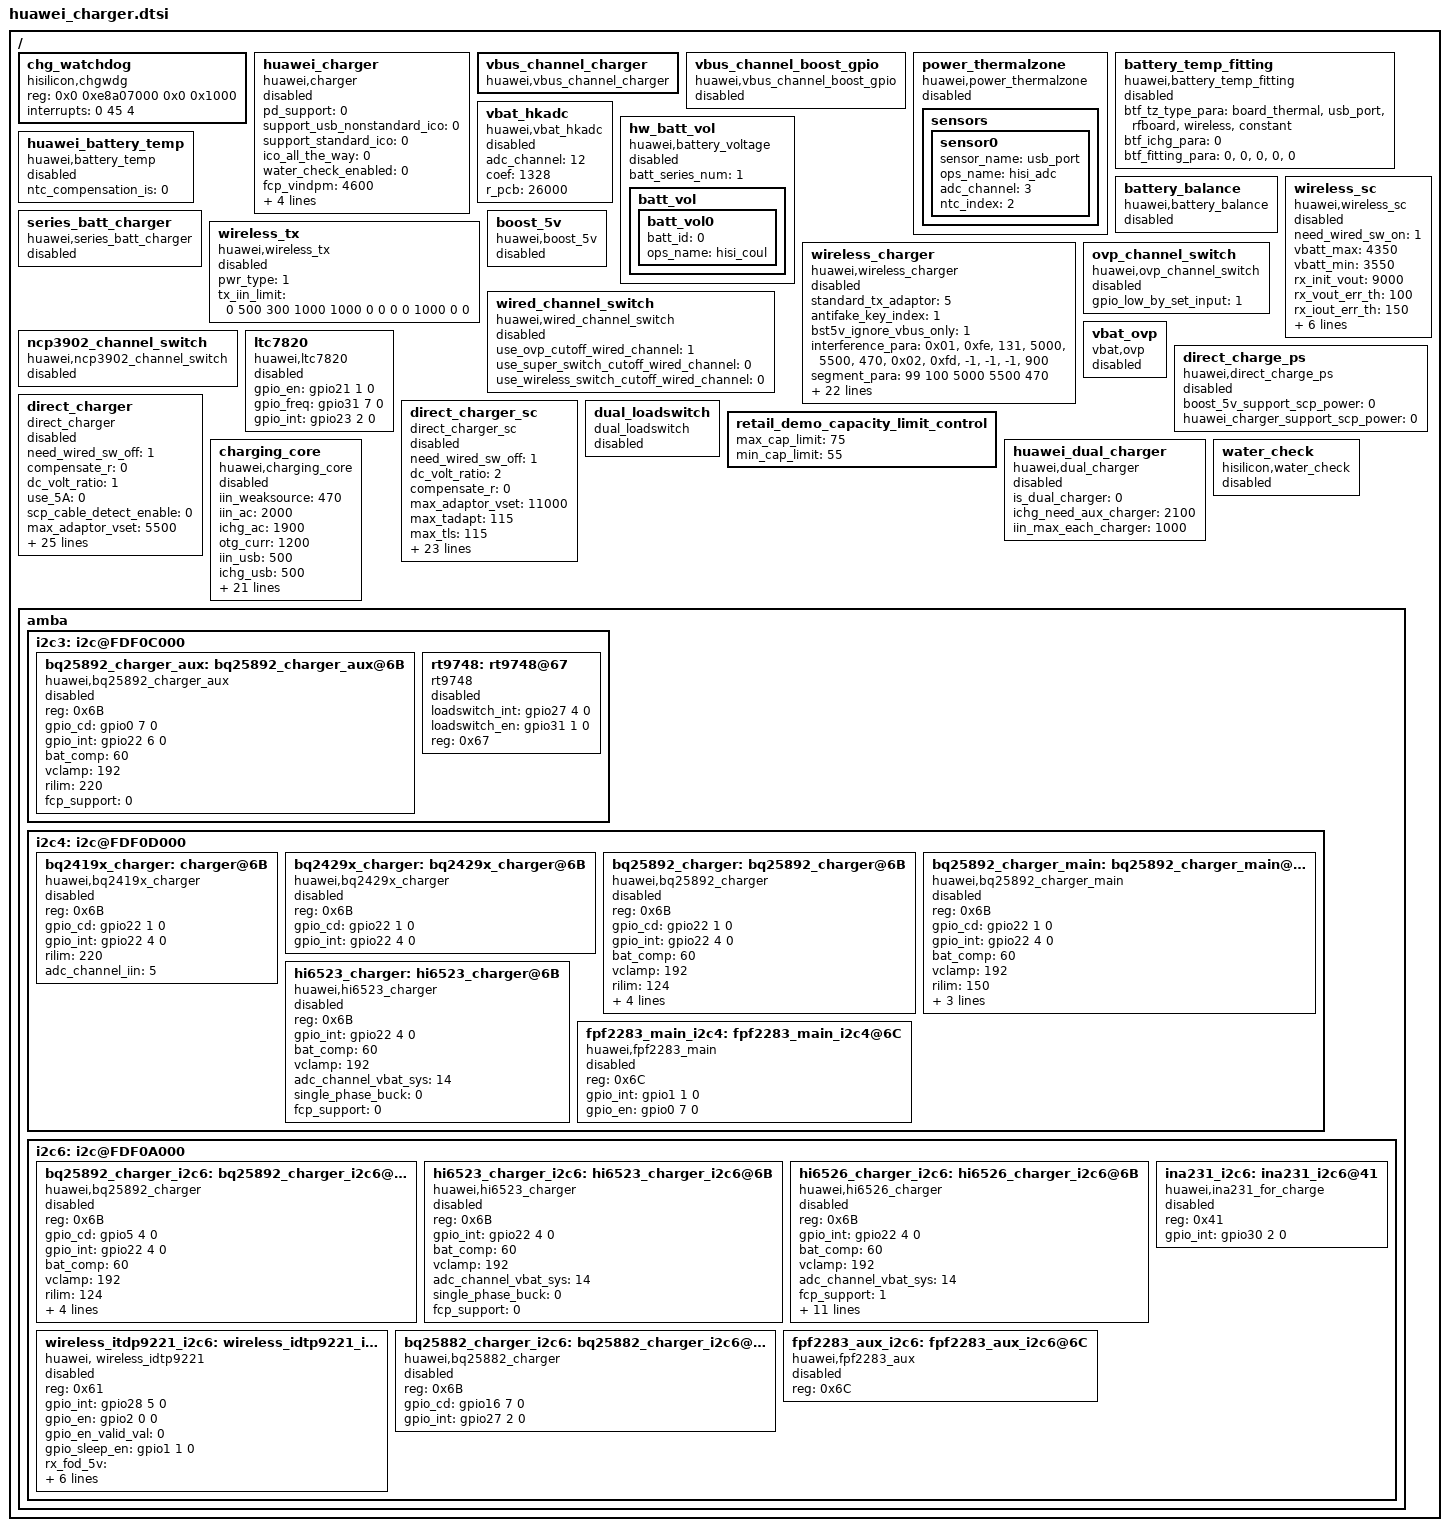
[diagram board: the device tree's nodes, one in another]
/ {
	chg_watchdog {
		compatible = "hisilicon,chgwdg";
		reg = <0x0 0xe8a07000 0x0 0x1000>;
		interrupts = <0 45 4>;
		status = "ok";
	};
	huawei_charger: huawei_charger{
		compatible = "huawei,charger";
		pd_support = <0>;
		support_usb_nonstandard_ico = <0>;
		support_standard_ico = <0>;
		ico_all_the_way = <0>;
		water_check_enabled = <0>;
		fcp_vindpm = <4600>;
		pd_cur_trans_ratio = <88>;
		non_standard_charger_dsm = <0>;
		charger_removed_dsm = <0>;
		check_ibias_sleep_time = <250>;
		status = "disabled";
	};

	vbus_channel_charger: vbus_channel_charger {
		compatible = "huawei,vbus_channel_charger";
		status = "ok";
	};

	vbus_channel_boost_gpio: vbus_channel_boost_gpio {
		compatible = "huawei,vbus_channel_boost_gpio";
		status = "disabled";
	};

	power_thermalzone: power_thermalzone {
		compatible = "huawei,power_thermalzone";
		status = "disabled";
		sensors{
			sensor0{
				sensor_name = "usb_port";
				ops_name = "hisi_adc";
				adc_channel = <3>;
				ntc_index = <2>;
			};
		};
	};
	battery_temp_fitting: battery_temp_fitting {
		compatible = "huawei,battery_temp_fitting";
		status = "disabled";
		btf_tz_type_para = "board_thermal", "usb_port", "rfboard", "wireless", "constant";
		btf_ichg_para = "0";
		btf_fitting_para = "0", "0", "0", "0", "0";
	};
	vbat_hkadc: vbat_hkadc {
		compatible = "huawei,vbat_hkadc";
		status = "diabled";
		adc_channel = <12>;
		coef = <1328>;
		r_pcb = <26000>;
	};
	hw_batt_vol: hw_batt_vol {
		compatible = "huawei,battery_voltage";
		status = "disabled";
		batt_series_num = <1>;
		batt_vol {
			batt_vol0{
				batt_id = <0>;
				ops_name = "hisi_coul";
			};
		};
	};
	huawei_battery_temp: huawei_battery_temp {
		compatible = "huawei,battery_temp";
		status = "disabled";
		ntc_compensation_is = <0>;
	};
	battery_balance: battery_balance {
		compatible = "huawei,battery_balance";
		status = "disabled";
	};
	series_batt_charger: series_batt_charger {
		compatible = "huawei,series_batt_charger";
		status = "disabled";
	};
	wireless_sc: wireless_sc {
		compatible = "huawei,wireless_sc";
		need_wired_sw_on = <1>;
		vbatt_max = <4350>;
		vbatt_min = <3550>;
		rx_init_vout = <9000>;
		rx_vout_err_th = <100>;
		rx_iout_err_th = <150>;
		rx_init_delt_vout = <300>;
		volt_ratio = <2>;
		ctrl_interval = <300>;
		calc_interval = <100>;
		vstep = <100>;
		volt_para = <
			4360 1250 600
		>;
		status = "disabled";
	};
	wireless_tx: wireless_tx {
		compatible = "huawei,wireless_tx";
		pwr_type = <1>; //0:VBUS_OTG 1:5VBST_OTG 2:SP-BST
		tx_iin_limit = <0 500 300 1000 1000 0 0 0 0 1000 0 0>;
		status = "disabled";
	};
	wireless_charger: wireless_charger {
		compatible = "huawei,wireless_charger";
		standard_tx_adaptor = <5>;/*fcp*/
		antifake_key_index = <1>;
		bst5v_ignore_vbus_only = <1>;
		interference_para =
			"0x01", "0xfe", "131", "5000", "5500", "470",
			"0x02", "0xfd", "-1",  "-1",   "-1",   "900";
		segment_para = <
			99 100 5000 5500 470
		>;
		rx_vout_err_ratio = <81>; /*percent*/
		rx_iout_min = <130>;
		rx_iout_step = <350>;
		rx_iout_ctrl_para = <
			0     80    130
			80    350   470
			350   700   900
			700   800   1000
			800   900   1080
			900   1000  1200
			1000  9999  1300
		>;
		rx_mode_para =
			/*This table should be arranged in ascending order of power mode priority*/
			/*mode  tx_vout  tx_iout tx_vset  rx_vset  rx_iset vrect_lth tbatt cable cert  icon time expect_mode*/
			"5W",   "5000",  "500",  "5000",  "5500",  "1000", "5000",   "-1", "-1", "-1", "0", "-1",  "3",
			"7.5W", "9000",  "1500", "9000",  "9900",  "900",  "9000",   "-1", "-1", "-1", "0", "-1",  "2",
			"10W",  "9000",  "2000", "9000",  "9900",  "1080", "9000",   "-1", "-1", "1",  "1", "-1",  "3",
			"SC",   "9000",  "2000", "9000",  "9000",  "1250", "9000",   "45", "-1", "1",  "1", "-1",  "-1",
			"15W",  "11000", "2000", "12000", "12000", "1300", "11000",  "34", "-1", "1",  "1", "600", "-1";
		product_para = <
			12000 12000 1300
		>;
		tx_prop =
			"0x01", "SDP",     "0", "0", "5000", "470",
			"0x02", "CDP",     "0", "0", "5000", "1000",
			"0x03", "NON_STD", "0", "0", "5000", "1000",
			"0x04", "DCP",     "0", "0", "5000", "1000",
			"0x05", "FCP",     "0", "1", "9000", "2000",
			"0x06", "SCP",     "0", "1", "5000", "1000",
			"0x07", "PD",      "0", "1", "5000", "1000",
			"0x08", "QC",      "0", "1", "5000", "1000",
			"0x09", "OTG",     "0", "0", "5000", "470",
			"0xff", "ERR",     "0", "0", "5000", "1000";
		volt_mode = <
			0 5000
			1 9000
			2 12000
		>;
		status = "disabled";
	};
	boost_5v: boost_5v {
		compatible = "huawei,boost_5v";
		status = "disabled";
	};
	wired_channel_switch: wired_channel_switch {
		compatible = "huawei,wired_channel_switch";
		use_ovp_cutoff_wired_channel = <1>;
		use_super_switch_cutoff_wired_channel = <0>;
		use_wireless_switch_cutoff_wired_channel = <0>;
		status = "disabled";
	};
	ovp_channel_switch: ovp_channel_switch {
		compatible = "huawei,ovp_channel_switch";
		gpio_low_by_set_input = <1>;
		status = "disabled";
	};
	ncp3902_channel_switch: ncp3902_channel_switch {
		compatible = "huawei,ncp3902_channel_switch";
		status = "disabled";
	};
	vbat_ovp: vbat_ovp{
		compatible = "vbat,ovp";
		status = "disabled";
	};
	ltc7820: ltc7820 {
		compatible = "huawei,ltc7820";
		gpio_en = <&gpio21 1 0>;
		gpio_freq = <&gpio31 7 0>;
		gpio_int = <&gpio23 2 0>;
		status = "disabled";
	};
	direct_charge_ps: direct_charge_ps {
		compatible = "huawei,direct_charge_ps";
		boost_5v_support_scp_power = <0>;
		huawei_charger_support_scp_power = <0>;
		status = "disabled";
	};
	direct_charger: direct_charger{
		need_wired_sw_off = <1>;
		compensate_r = <0>;
		dc_volt_ratio = <1>;
		use_5A = <0>;
		scp_cable_detect_enable = <0>;
		max_adaptor_vset = <5500>;
		max_tadapt = <115>;
		max_tls = <115>;
		ibat_abnormal_th = <200>;
		first_cc_stage_timer_in_min = <0>;
		max_dc_bat_vol = <4350>;
		min_dc_bat_vol = <3550>;
		charge_control_interval = <5>;
		threshold_caculation_interval = <5>;
		safety_monitor_interval = <5>;
		scp_work_on_charger = <0>;
		init_adapter_vset = <4400>;
		init_delt_vset = <300>;
		vstep = <10>;
		delta_err = <200>;
		vol_err_th = <150>;
		full_path_res_max = <120>;
		standard_cable_full_path_res_max = <160>;
		max_current_for_none_standard_cable = <3000>;
		super_ico_current = <4000>;
		is_show_ico_first = <0>;
		adaptor_leakage_current_th = <300>;
		adaptor_detect_by_voltage = <0>;
		stage_need_to_jump = "-1";
		temp_para =
			"-32767", "10", "0",
			"10", "45", "4750",
			"45", "32767", "0";
		compatible = "direct_charger";
		status = "disabled";
	};
	direct_charger_sc: direct_charger_sc{
		compatible = "direct_charger_sc";
		need_wired_sw_off = <1>;
		dc_volt_ratio = <2>;
		compensate_r = <0>;
		max_adaptor_vset = <11000>;
		max_tadapt = <115>;
		max_tls = <115>;
		ibat_abnormal_th = <200>;
		first_cc_stage_timer_in_min = <0>;
		max_dc_bat_vol = <4380>;
		min_dc_bat_vol = <3550>;
		charge_control_interval = <5>;
		threshold_caculation_interval = <5>;
		safety_monitor_interval = <5>;
		scp_work_on_charger = <0>;
		init_adapter_vset = <8800>;
		init_delt_vset = <600>;
		vstep = <20>;
		delta_err = <300>;
		vol_err_th = <150>;
		full_path_res_max = <120>;
		standard_cable_full_path_res_max = <160>;
		max_current_for_none_standard_cable = <6000>;
		super_ico_current = <4000>;
		is_show_ico_first = <0>;
		adaptor_leakage_current_th = <300>;
		adaptor_detect_by_voltage = <0>;
		stage_need_to_jump = "-1";
		temp_para =
			"-32767", "10", "0",
			"10", "45", "4750",
			"45", "32767", "0";
		status = "disabled";
	};
	dual_loadswitch: dual_loadswitch{
		compatible = "dual_loadswitch";
		status = "disabled";
	};
	retail_demo_capacity_limit_control: retail_demo_capacity_limit_control{
		max_cap_limit = "75";
		min_cap_limit = "55";
	};
	huawei_dual_charger: huawei_dual_charger{
		compatible = "huawei,dual_charger";
		is_dual_charger = <0>;
		ichg_need_aux_charger = <2100>;
		iin_max_each_charger = <1000>;
		status = "disabled";
	};
	charging_core:charging_core{
		compatible = "huawei,charging_core";
		iin_weaksource = <470>;
		iin_ac = <2000>;
		ichg_ac = <1900>;
		otg_curr = <1200>;
		iin_usb = <500>;
		ichg_usb = <500>;
		iin_nonstd = <1200>;
		ichg_nonstd = <1000>;
		iin_bc_usb = <1500>;
		ichg_bc_usb = <1400>;
		iin_wireless = <1300>;
		ichg_wireless = <3000>;
		iin_vr = <1000>;
		ichg_vr = <1000>;
		iin_typech = <2000>;
		ichg_typech = <2100>;
		typec_support = <0>;
		high_temp_limit = <1>;
		iterm = <100>;
		ichrg_pre_limit = <128>;
		segment_type = <0>;
		vdpm_control_type = <1>;
		vdpm_buf_limit = <100>;
		vdpm_para =
			"-32767", "4100", "4500", "50",
			"4150", "32767", "4625", "50";
		inductance_para =
			"-32767", "15", "1600", "0",
			"15", "32767", "1700", "0";
		status = "disabled";
	};
	water_check:water_check{
		compatible = "hisilicon,water_check";
		status = "disabled";
	};
	amba {
		i2c3: i2c@FDF0C000{
			bq25892_charger_aux: bq25892_charger_aux@6B{
				compatible = "huawei,bq25892_charger_aux";
				reg = <0x6B>;
				gpio_cd = <&gpio0 7 0>;
				gpio_int = <&gpio22 6 0>;
				bat_comp = <60>;
				vclamp = <192>;
				rilim = <220>;
				fcp_support = <0>;
				status = "disabled";
			};

			rt9748: rt9748@67 {
				compatible = "rt9748";
				loadswitch_int = <&gpio27 4 0>;
				loadswitch_en = <&gpio31 1 0>;
				reg = <0x67>;
				status = "disabled";
			};
		};
		i2c4: i2c@FDF0D000 {
			bq2419x_charger: charger@6B{
				compatible = "huawei,bq2419x_charger";
				reg = <0x6B>;
				gpio_cd = <&gpio22 1 0>;
				gpio_int = <&gpio22 4 0>;
				rilim = <220>;
				adc_channel_iin = <5>;
				status = "disabled";
			};

			bq2429x_charger: bq2429x_charger@6B{
				compatible = "huawei,bq2429x_charger";
				reg = <0x6B>;
				gpio_cd = <&gpio22 1 0>;
				gpio_int = <&gpio22 4 0>;
				status = "disabled";
			};
			bq25892_charger: bq25892_charger@6B{
				compatible = "huawei,bq25892_charger";
				reg = <0x6B>;
				gpio_cd = <&gpio22 1 0>;
				gpio_int = <&gpio22 4 0>;
				bat_comp = <60>;
				vclamp = <192>;
				rilim = <124>;
				adc_channel_iin = <5>;
				adc_channel_vbat_sys = <14>;
				fcp_support = <0>;
				ico_current_mode = <0>;
				/*0:final current is the max of original and ico current
				 *1:final current is ico current
				 */
				status = "disabled";
			};
			bq25892_charger_main: bq25892_charger_main@6B{
				compatible = "huawei,bq25892_charger_main";
				reg = <0x6B>;
				gpio_cd = <&gpio22 1 0>;
				gpio_int = <&gpio22 4 0>;
				bat_comp = <60>;
				vclamp = <192>;
				rilim = <150>;
				adc_channel_iin = <5>;
				adc_channel_vbat_sys = <14>;
				fcp_support = <0>;
				status = "disabled";
			};
			hi6523_charger: hi6523_charger@6B{
				compatible = "huawei,hi6523_charger";
				reg = <0x6B>;
				gpio_int = <&gpio22 4 0>;
				bat_comp = <60>;
				vclamp = <192>;
				adc_channel_vbat_sys = <14>;
				single_phase_buck = <0>;
				fcp_support = <0>;
				status = "disabled";
			};
			fpf2283_main_i2c4: fpf2283_main_i2c4@6C {
				compatible = "huawei,fpf2283_main";
				reg = <0x6C>;
				gpio_int = <&gpio1 1 0>;
				gpio_en = <&gpio0 7 0>;
				status = "disabled";
			};

		};
		i2c6: i2c@FDF0A000 {
			bq25892_charger_i2c6: bq25892_charger_i2c6@6B{
				compatible = "huawei,bq25892_charger";
				reg = <0x6B>;
				gpio_cd = <&gpio5 4 0>;
				gpio_int = <&gpio22 4 0>;
				bat_comp = <60>;
				vclamp = <192>;
				rilim = <124>;
				adc_channel_iin = <5>;
				adc_channel_vbat_sys = <14>;
				fcp_support = <0>;
				ico_current_mode = <0>;
				/*0:final current is the max of original and ico current
				*1:final current is ico current
				*/
				status = "disabled";
			};
			hi6523_charger_i2c6: hi6523_charger_i2c6@6B{
				compatible = "huawei,hi6523_charger";
				reg = <0x6B>;
				gpio_int = <&gpio22 4 0>;
				bat_comp = <60>;
				vclamp = <192>;
				adc_channel_vbat_sys = <14>;
				single_phase_buck = <0>;
				fcp_support = <0>;
				status = "disabled";
            };
            hi6526_charger_i2c6: hi6526_charger_i2c6@6B{
				compatible = "huawei,hi6526_charger";
				reg = <0x6B>;
				gpio_int = <&gpio22 4 0>;
				bat_comp = <60>;
				vclamp = <192>;
				adc_channel_vbat_sys = <14>;
				fcp_support = <1>;
				scp_support = <1>;
				lvc_ibat_regulator = <12200>;
				lvc_vbat_regulator = <4500>;
				lvc_vout_regulator = <4550>;
				lvc_ibus_regulator = <5600>;
				sc_ibat_regulator = <12200>;
				sc_vbat_regulator = <4500>;
				sc_vout_regulator = <4550>;
				sc_ibus_regulator = <5600>;
				lvc_vusb2vbus_drop_en = <1>;
				sc_vusb2vbus_drop_en = <1>;
				status = "disabled";
            };
			wireless_itdp9221_i2c6: wireless_idtp9221_i2c6@61 {
				compatible = "huawei, wireless_idtp9221";
				reg = <0x61>;
				gpio_int = <&gpio28 5 0>;
				gpio_en = <&gpio2 0 0>;
				gpio_en_valid_val = <0>;
				gpio_sleep_en = <&gpio1 1 0>;
				rx_fod_5v = <5313 4256 4248 4248 4251 4252 5140 0>;
				rx_fod_9v = <11670 11656 10376 10374 6534 6534 0 0>;
				rx_fod_12v = <11670 11656 10376 10374 6534 6534 0 0>;
				rx_ss_good_lth = <95>;
				status = "disabled";
			};
			ina231_i2c6: ina231_i2c6@41 {
				compatible = "huawei,ina231_for_charge";
				reg = <0x41>;
				gpio_int = <&gpio30 2 0>;
				status = "disabled";
			};
			bq25882_charger_i2c6: bq25882_charger_i2c6@6B{
				compatible = "huawei,bq25882_charger";
				reg = <0x6B>;
				gpio_cd = <&gpio16 7 0>;
				gpio_int = <&gpio27 2 0>;
				status = "disabled";
			};
			fpf2283_aux_i2c6: fpf2283_aux_i2c6@6C {
				compatible = "huawei,fpf2283_aux";
				reg = <0x6C>;
				status = "disabled";
			};
		};
	};
};
